# NUC1262AE register map
File version: 1.0
Registers are 32-bit, read-write, reset 0x0 unless marked. A register's access mark holds for its fields unless they carry their own. Offsets are from the block's base; [hi:lo] are bit positions; {n}, {i} and the like mark numbered series.

## SYS — SYS Register Map
Base 0x50000000
0x00 SYS_PDID ro reset not defined — Part Device Identification Number Register
  [31:0] PDID — Part Device Identification Number (Read Only). This register reflects device part number code. Software can read this register to identify which device is used.
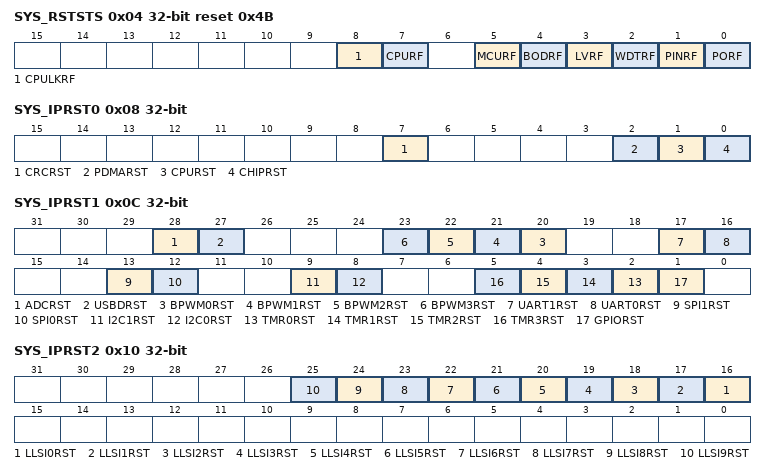
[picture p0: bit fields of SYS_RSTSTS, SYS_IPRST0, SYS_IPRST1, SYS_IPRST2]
0x04 SYS_RSTSTS reset 0x4B — System Reset Status Register
  [8] CPULKRF — CPU Lockup Reset Flag. The CPU lockup reset flag is set by hardware If Cortex-M23 lockup happened. Note 1: This bit can be cleared by software writing 1. Note 2: When CPU lockup happened under ICE is connected, this flag will be set to 1 but chip will not reset.
    0=No reset from CPU lockup happened; 1=The Cortex-M23 lockup happened and chip is reset
  [7] CPURF — CPU Reset Flag. The CPU reset flag is set by hardware if software writes CPURST (SYS_IPRST0[1]) 1 to reset Cortex-M23 Core and Flash Memory Controller (FMC). Note: This bit can be cleared by software writing 1.
    0=No reset from CPU; 1=The Cortex-M23 Core and FMC are reset by software setting CPURST to 1
  [5] MCURF — MCU Reset Flag. The MCU reset flag is set by the 'Reset Signal' from the Cortex-M23 Core to indicate the previous reset source. Note: This bit can be cleared by software writing 1.
    0=No reset from Cortex-M23; 1=The Cortex-M23 had issued the reset signal to reset the system by writing 1 to the bit SYSRESETREQ(AIRCR[2], Application Interrupt and Reset Control Register, address = 0xE000ED0C) in system control registers of Cortex-M23 core
  [4] BODRF — BOD Reset Flag. The BOD reset flag is set by the 'Reset Signal' from the Brown-out Detector to indicate the previous reset source. Note: This bit can be cleared by software writing 1.
    0=No reset from BOD; 1=The BOD had issued the reset signal to reset the system
  [3] LVRF — LVR Reset Flag. The LVR reset flag is set by the 'Reset Signal' from the Low Voltage Reset Controller to indicate the previous reset source. Note: This bit can be cleared by software writing 1.
    0=No reset from LVR; 1=LVR controller had issued the reset signal to reset the system
  [2] WDTRF — WDT Reset Flag. The WDT reset flag is set by the 'Reset Signal' from the Watchdog Timer or Window Watchdog Timer to indicate the previous reset source. Note 1: This bit can be cleared by software writing 1. Note 2: Watchdog Timer register RSTF(WDT_CTL[2]) bit is set if the system has been reset by WDT time-out reset. Window Watchdog Timer register WWDTRF(WWDT_STATUS[1]) bit is set if the system has been reset by WWDT time-out reset.
    0=No reset from watchdog timer or window watchdog timer; 1=The watchdog timer or window watchdog timer had issued the reset signal to reset the system
  [1] PINRF — nRESET Pin Reset Flag. The nRESET pin reset flag is set by the 'Reset Signal' from the nRESET Pin to indicate the previous reset source. Note: This bit can be cleared by software writing 1.
    0=No reset from nRESET pin; 1=Pin nRESET had issued the reset signal to reset the system
  [0] PORF — POR Reset Flag. The POR reset flag is set by the 'Reset Signal' from the Power-on Reset (POR) Controller or bit CHIPRST (SYS_IPRST0[0]) to indicate the previous reset source. Note: This bit can be cleared by software writing 1.
    0=No reset from POR or CHIPRST; 1=Power-on Reset (POR) or CHIPRST had issued the reset signal to reset the system
0x08 SYS_IPRST0 — Peripheral Reset Control Register 0
  [7] CRCRST — CRC Calculation Controller Reset (Write Protect). Set this bit to 1 will generate a reset signal to the CRC calculation controller. User needs to set this bit to 0 to release from the reset state. Note: This bit is write protected. Refer to the SYS_REGLCTL register.
    0=CRC calculation controller normal operation; 1=CRC calculation controller reset
  [2] PDMARST — PDMA Controller Reset (Write Protect). Setting this bit to 1 will generate a reset signal to the PDMA. User needs to set this bit to 0 to release from reset state. Note: This bit is write protected. Refer to the SYS_REGLCTL register.
    0=PDMA controller normal operation; 1=PDMA controller reset
  [1] CPURST — Processor Core One-shot Reset (Write Protect). Setting this bit will only reset the processor core and Flash Memory Controller (FMC), and this bit will automatically return to 0 after the 2 clock cycles. Note: This bit is write protected. Refer to the SYS_REGLCTL register.
    0=Processor core normal operation; 1=Processor core one-shot reset
  [0] CHIPRST — Chip One-shot Reset (Write Protect). Setting this bit will reset the whole chip, including Processor core and all peripherals, and this bit will automatically return to 0 after the 2 clock cycles. The CHIPRST is same as the POR reset, all the chip controllers is reset and the chip setting from Flash are also reload. About the difference between CHIPRST and SYSRESETREQ(AIRCR[2]), please refer to section 6.2.2. Note: This bit is write protected. Refer to the SYS_REGLCTL register.
    0=Chip normal operation; 1=Chip one-shot reset
0x0C SYS_IPRST1 — Peripheral Reset Control Register 1
  [28] ADCRST — ADC Controller Reset
    0=ADC controller normal operation; 1=ADC controller reset
  [27] USBDRST — USB Device Controller Reset
    0=USB device controller normal operation; 1=USB device controller reset
  [n+20] BPWM{n}RST (n=0..3) — BPWM{n} Controller Reset
    0=BPWM{n} controller normal operation; 1=BPWM{n} controller reset
  [17] UART1RST — UART1 Controller Reset
    0=UART1 controller normal operation; 1=UART1 controller reset
  [16] UART0RST — UART0 Controller Reset
    0=UART0 controller normal operation; 1=UART0 controller reset
  [13] SPI1RST — SPI1 Controller Reset
    0=SPI1 controller normal operation; 1=SPI1 controller reset
  [12] SPI0RST — SPI0 Controller Reset
    0=SPI0 controller normal operation; 1=SPI0 controller reset
  [9] I2C1RST — I2C1 Controller Reset
    0=I2C1 controller normal operation; 1=I2C1 controller reset
  [8] I2C0RST — I2C0 Controller Reset
    0=I2C0 controller normal operation; 1=I2C0 controller reset
  [n+2] TMR{n}RST (n=0..3) — Timer{n} Controller Reset
    0=Timer{n} controller normal operation; 1=Timer{n} controller reset
  [1] GPIORST — GPIO Controller Reset
    0=GPIO controller normal operation; 1=GPIO controller reset
0x10 SYS_IPRST2 — Peripheral Reset Control Register 2
  [n+16] LLSI{n}RST (n=0..9) — LLSI{n} Controller Reset
    0=LED Lighting Strip Interface {n} controller normal operation; 1=LED Lighting Strip Interface {n} controller reset
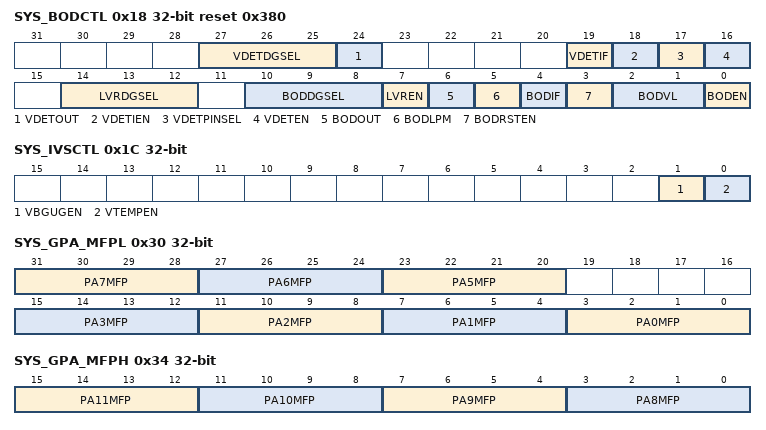
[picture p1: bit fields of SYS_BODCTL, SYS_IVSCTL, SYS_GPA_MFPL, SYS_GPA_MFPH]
0x18 SYS_BODCTL reset 0x380 (reset mask 0xFFFFFFF0) — Brown-out Detector Control Register
  [27:25] VDETDGSEL — Voltage Detector Output De-glitch Time Select (Write Protect). Note: These bits are write protected. Refer to the SYS_REGLCTL register.
    0=VDET output is sampled by VDET clock; 1=16 system clock (HCLK); 2=32 system clock (HCLK); 3=64 system clock (HCLK); 4=128 system clock (HCLK); 5=256 system clock (HCLK); 6=512 system clock (HCLK); 7=1024 system clock (HCLK)
  [24] VDETOUT — Voltage Detector Output Status. It means the detected voltage is lower than Band-gap. If the VDETEN is 0, VDET function is disabled. This bit always responds 0.
    0=VDET output status is 0; 1=VDET output status is 1
  [19] VDETIF — Voltage Detector Interrupt Flag. Note: This bit can be cleared by software writing 1.
    0=VDET does not detect any voltage draft at external pin down through or up through the voltage of Band-gap; 1=When VDET detects the external pin is dropped down through the voltage of Band-gap or the external pin is raised up through the voltage of Band-gap, this bit is set to 1 and the voltage detector interrupt is requested if voltage detector interrupt is enabled
  [18] VDETIEN — Voltage Detector Interrupt Enable Bit
    0=VDET interrupt Disabled; 1=VDET interrupt Enabled
  [17] VDETPINSEL — Voltage Detector External Input Voltage Pin Selection. Note 1: If VDET_P0 is selected, multi-function pin must be selected correctly in PB0MFP (SYS_GPB_MFPL[3:0]). Note 2: If VDET_P1 is selected, multi-function pin must be selected correctly in PB1MFP (SYS_GPB_MFPL[7:4]).
    0=The input voltage is from VDET_P0 (PB.0); 1=The input voltage is from VDET_P1 (PB.1)
  [16] VDETEN — Voltage Detector Enable Bit. Note 1: This function is still active in whole chip Power-down mode. Note 2: This function need use LIRC or LXT as VDET clock source, which is selected in VDETCKSEL (CLK_BODCLK[0]). Note2: The input pin for VDET detect voltage is selectable by VDETPINSEL (SYS_BODCTL[17]).
    0=VDET detect external input voltage function Disabled; 1=VDET detect external input voltage function Enabled
  [14:12] LVRDGSEL — LVR Output De-glitch Time Select (Write Protect). Note: These bits are write protected. Refer to the SYS_REGLCTL register.
    0=Without de-glitch function; 1=4 system clock (HCLK); 2=8 system clock (HCLK); 3=16 system clock (HCLK); 4=32 system clock (HCLK); 5=64 system clock (HCLK); 6=128 system clock (HCLK); 7=256 system clock (HCLK)
  [10:8] BODDGSEL — Brown-out Detector Output De-glitch Time Select (Write Protect). Note: These bits are write protected. Refer to the SYS_REGLCTL register.
    0=BOD output is sampled by RC10K clock; 1=4 system clock (HCLK); 2=8 system clock (HCLK); 3=16 system clock (HCLK); 4=32 system clock (HCLK); 5=64 system clock (HCLK); 6=128 system clock (HCLK); 7=256 system clock (HCLK)
  [7] LVREN — Low Voltage Reset Enable Bit (Write Protect). The LVR function resets the chip when the input power voltage is lower than LVR circuit setting. LVR function is enabled by default. Note 1: After enabling the bit, the LVR function will be active with 200us delay for LVR output stable (default). Note 2: This bit is write protected. Refer to the SYS_REGLCTL register.
    0=Low Voltage Reset function Disabled; 1=Low Voltage Reset function Enabled
  [6] BODOUT — Brown-out Detector Output Status. It means the detected voltage is lower than BODVL setting. If the BODEN is 0, BOD function is disabled. This bit always responds 0.
    0=Brown-out Detector output status is 0; 1=Brown-out Detector output status is 1
  [5] BODLPM — Brown-out Detector Low Power Mode (Write Protect). Note 1: The BOD consumes about 100uA in normal mode, the low power mode can reduce the current to about 1/10 but slow the BOD response. Note 2: This bit is write protected. Refer to the SYS_REGLCTL register.
    0=BOD operated in normal mode (default); 1=BOD Low Power mode Enabled
  [4] BODIF — Brown-out Detector Interrupt Flag. Note: This bit can be cleared by software writing 1.
    0=Brown-out Detector does not detect any voltage draft at VDD down through or up through the voltage of BODVL setting; 1=When Brown-out Detector detects the VDD is dropped down through the voltage of BODVL setting or the VDD is raised up through the voltage of BODVL setting, this bit is set to 1 and the brown-out interrupt is requested if brown-out interrupt is enabled
  [3] BODRSTEN — Brown-out Reset Enable Bit (Write Protect). The default value is set by Flash controller user configuration register CBORST(CONFIG0[20]) bit. Note 1: While the Brown-out Detector function is enabled (BODEN high) and BOD reset function is enabled (BODRSTEN high), BOD will assert a signal to reset chip when the detected voltage is lower than the threshold (BODOUT high). While the BOD function is enabled (BODEN high) and BOD interrupt function is enabled (BODRSTEN low), BOD will assert an interrupt if BODOUT is high. BOD interrupt will keep till to the BODEN set to 0. BOD interrupt can be blocked by disabling the NVIC BOD interrupt or disabling BOD function (set BODEN low). Note 2: This bit is write protected. Refer to the SYS_REGLCTL register.
    0=Brown-out 'INTERRUPT' function Enabled; 1=Brown-out 'RESET' function Enabled
  [2:1] BODVL — Brown-out Detector Threshold Voltage Selection (Write Protect). The default value is set by Flash controller user configuration register CBOV (CONFIG0 [22:21]). Note: These bits are write protected. Refer to the SYS_REGLCTL register.
    0=Brown-Out Detector threshold voltage is 2.2V; 1=Brown-Out Detector threshold voltage is 2.7V; 2=Brown-Out Detector threshold voltage is 3.7V; 3=Brown-Out Detector threshold voltage is 4.5V
  [0] BODEN — Brown-out Detector Enable Bit (Write Protect). The default value is set by Flash controller user configuration register CBODEN (CONFIG0 [23]). Note: This bit is write protected. Refer to the SYS_REGLCTL register.
    0=Brown-out Detector function Disabled; 1=Brown-out Detector function Enabled
0x1C SYS_IVSCTL — Internal Voltage Source Control Register
  [1] VBGUGEN — Band-gap VBG Unity Gain Buffer Enable Bit. This bit is used to enable/disable Band-gap VBG unity gain buffer function. Note: After this bit is set to 1, the value of VBG unity gain buffer output voltage can be obtained from ADC conversion result. Please refer to ADC function chapter for details.
    0=VBG unity gain buffer function Disabled (default); 1=VBG unity gain buffer function Enabled
  [0] VTEMPEN — Temperature Sensor Enable Bit. This bit is used to enable/disable temperature sensor function. Note: After this bit is set to 1, the value of temperature sensor output can be obtained from ADC conversion result. Please refer to ADC function chapter for details.
    0=Temperature sensor function Disabled (default); 1=Temperature sensor function Enabled
0x24 SYS_PORCTL — Power-on Reset Controller Register
  [15:0] POROFF — Power-on Reset Enable Bit (Write Protect). When powered on, the POR circuit generates a reset signal to reset the whole chip function, but noise on the power may cause the POR active again. User can disable internal POR circuit to avoid unpredictable noise to cause chip reset by writing 0x5AA5 to this field. The POR function will be active again when this field is set to another value or chip is reset by other reset source, including: nRESET, Watchdog, LVR reset, BOD reset, ICE reset command and the software-chip reset function. Note: These bits are write protected. Refer to the SYS_REGLCTL register.
0x30 SYS_GPA_MFPL — GPIOA Low Byte Multiple Function Control Register
  [31:28] PA7MFP — PA.7 Multi-function Pin Selection
  [27:24] PA6MFP — PA.6 Multi-function Pin Selection
  [23:20] PA5MFP — PA.5 Multi-function Pin Selection
  [15:12] PA3MFP — PA.3 Multi-function Pin Selection
  [11:8] PA2MFP — PA.2 Multi-function Pin Selection
  [7:4] PA1MFP — PA.1 Multi-function Pin Selection
  [3:0] PA0MFP — PA.0 Multi-function Pin Selection
0x34 SYS_GPA_MFPH — GPIOA High Byte Multiple Function Control Register
  [15:12] PA11MFP — PA.11 Multi-function Pin Selection
  [11:8] PA10MFP — PA.10 Multi-function Pin Selection
  [7:4] PA9MFP — PA.9 Multi-function Pin Selection
  [3:0] PA8MFP — PA.8 Multi-function Pin Selection
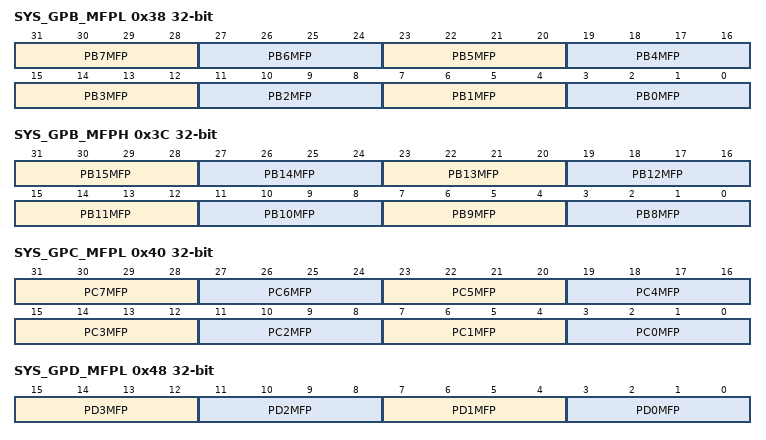
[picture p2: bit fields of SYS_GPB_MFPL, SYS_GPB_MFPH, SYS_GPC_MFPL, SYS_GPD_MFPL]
0x38 SYS_GPB_MFPL — GPIOB Low Byte Multiple Function Control Register
  [31:28] PB7MFP — PB.7 Multi-function Pin Selection
  [27:24] PB6MFP — PB.6 Multi-function Pin Selection
  [23:20] PB5MFP — PB.5 Multi-function Pin Selection
  [19:16] PB4MFP — PB.4 Multi-function Pin Selection
  [15:12] PB3MFP — PB.3 Multi-function Pin Selection
  [11:8] PB2MFP — PB.2 Multi-function Pin Selection
  [7:4] PB1MFP — PB.1 Multi-function Pin Selection
  [3:0] PB0MFP — PB.0 Multi-function Pin Selection
0x3C SYS_GPB_MFPH — GPIOB High Byte Multiple Function Control Register
  [31:28] PB15MFP — PB.15 Multi-function Pin Selection
  [27:24] PB14MFP — PB.14 Multi-function Pin Selection
  [23:20] PB13MFP — PB.13 Multi-function Pin Selection
  [19:16] PB12MFP — PB.12 Multi-function Pin Selection
  [15:12] PB11MFP — PB.11 Multi-function Pin Selection
  [11:8] PB10MFP — PB.10 Multi-function Pin Selection
  [7:4] PB9MFP — PB.9 Multi-function Pin Selection
  [3:0] PB8MFP — PB.8 Multi-function Pin Selection
0x40 SYS_GPC_MFPL — GPIOC Low Byte Multiple Function Control Register
  [31:28] PC7MFP — PC.7 Multi-function Pin Selection
  [27:24] PC6MFP — PC.6 Multi-function Pin Selection
  [23:20] PC5MFP — PC.5 Multi-function Pin Selection
  [19:16] PC4MFP — PC.4 Multi-function Pin Selection
  [15:12] PC3MFP — PC.3 Multi-function Pin Selection
  [11:8] PC2MFP — PC.2 Multi-function Pin Selection
  [7:4] PC1MFP — PC.1 Multi-function Pin Selection
  [3:0] PC0MFP — PC.0 Multi-function Pin Selection
0x44 SYS_GPC_MFPH — GPIOC High Byte Multiple Function Control Register
  [27:24] PC14MFP — PC14 Multi-function Pin Selection
0x48 SYS_GPD_MFPL — GPIOD Low Byte Multiple Function Control Register
  [15:12] PD3MFP — PD.3 Multi-function Pin Selection
  [11:8] PD2MFP — PD.2 Multi-function Pin Selection
  [7:4] PD1MFP — PD.1 Multi-function Pin Selection
  [3:0] PD0MFP — PD.0 Multi-function Pin Selection
0x4C SYS_GPD_MFPH — GPIOD High Byte Multiple Function Control Register
  [31:28] PD15MFP — PD.15 Multi-function Pin Selection
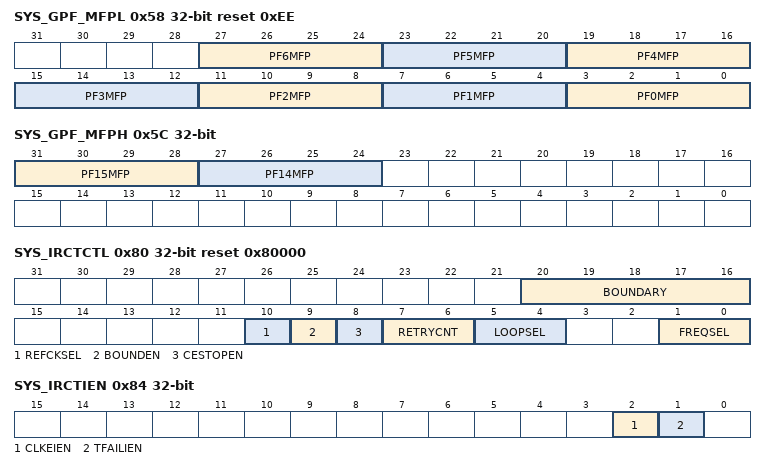
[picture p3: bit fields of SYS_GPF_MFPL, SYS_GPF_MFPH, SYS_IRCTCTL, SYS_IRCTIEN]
0x58 SYS_GPF_MFPL reset 0xEE — GPIOF Low Byte Multiple Function Control Register
  [27:24] PF6MFP — PF.6 Multi-function Pin Selection
  [23:20] PF5MFP — PF.5 Multi-function Pin Selection
  [19:16] PF4MFP — PF.4 Multi-function Pin Selection
  [15:12] PF3MFP — PF.3 Multi-function Pin Selection
  [11:8] PF2MFP — PF.2 Multi-function Pin Selection
  [7:4] PF1MFP — PF.1 Multi-function Pin Selection
  [3:0] PF0MFP — PF.0 Multi-function Pin Selection
0x5C SYS_GPF_MFPH — GPIOF High Byte Multiple Function Control Register
  [31:28] PF15MFP — PF.15 Multi-function Pin Selection
  [27:24] PF14MFP — PF.14 Multi-function Pin Selection
0x80 SYS_IRCTCTL reset 0x80000 — HIRC Trim Control Register
  [20:16] BOUNDARY — Boundary Selection. Fill the boundary range from 0x1 to 0x1F, 0x0 is reserved. Note: This field is effective only when the BOUNDEN(SYS_IRCTCTL[9]) is enabled.
  [10] REFCKSEL — Reference Clock Selection
    0=HIRC trim reference clock is from LXT (32.768 kHz); 1=HIRC trim reference clock is from USB synchronous mode packet
  [9] BOUNDEN — Boundary Enable Bit
    0=Boundary function Disabled; 1=Boundary function Enabled
  [8] CESTOPEN — Clock Error Stop Enable Bit
    0=The trim operation is keep going if clock is inaccurate; 1=The trim operation is stopped if clock is inaccurate
  [7:6] RETRYCNT — Trim Value Update Limitation Count. This field defines that how many times the auto trim circuit will try to update the HIRC trim value before the frequency of HIRC locked. Once the HIRC locked, the internal trim value update counter will be reset. If the trim value update counter reached this limitation value and frequency of HIRC is still not locked, the auto trim operation will be disabled and FREQSEL(SYS_IRCTCTL[1:0]) will be cleared to 00.
    0=Trim retry count limitation is 64 loops; 1=Trim retry count limitation is 128 loops; 2=Trim retry count limitation is 256 loops; 3=Trim retry count limitation is 512 loops
  [5:4] LOOPSEL — Trim Calculation Loop Selection. This field defines that trim value calculation is based on how many clocks of reference clock (32.768 kHz, LXT). Note: For example, if LOOPSEL is set as 00, auto trim circuit will calculate trim value based on the average frequency difference in 4 clocks of reference clock.
    0=Trim value calculation is based on average difference in 4 clocks of reference clock; 1=Trim value calculation is based on average difference in 8 clocks of reference clock; 2=Trim value calculation is based on average difference in 16 clocks of reference clock; 3=Trim value calculation is based on average difference in 32 clocks of reference clock
  [1:0] FREQSEL — Trim Frequency Selection. This field indicates the target frequency of internal high speed RC oscillator (HIRC) auto trim. During auto trim operation, if clock error detected with CESTOPEN(SYS_IRCTCTL[8]) is set to 1 or trim retry limitation count reached, this field will be cleared to 00 automatically.
    0=Disable HIRC auto trim function; 1=Enable HIRC auto trim function and trim HIRC to 48 MHz
0x84 SYS_IRCTIEN — HIRC Trim Interrupt Enable Register
  [2] CLKEIEN — HIRC Clock Error Interrupt Enable Bit. This bit controls if CPU would get an interrupt while HIRC clock is inaccurate during auto trim operation. If this bit is set to1, and CLKERRIF(SYS_IRCTSTS[2]) is set during auto trim operation, an interrupt will be triggered to notify the clock frequency is inaccurate.
    0=Disable CLKERRIF(SYS_IRCTSTS[2]) status to trigger an interrupt to CPU; 1=Enable CLKERRIF(SYS_IRCTSTS[2]) status to trigger an interrupt to CPU
  [1] TFAILIEN — HIRC Trim Failure Interrupt Enable Bit. This bit controls if an interrupt will be triggered while HIRC trim value update limitation count reached and HIRC frequency still not locked on target frequency set by FREQSEL(SYS_IRCTCTL[1:0]). If this bit is high and TFAILIF(SYS_IRCTSTS[1]) is set during auto trim operation, an interrupt will be triggered to notify that HIRC trim value update limitation count reached.
    0=Disable TFAILIF(SYS_IRCTSTS[1]) status to trigger an interrupt to CPU; 1=Enable TFAILIF(SYS_IRCTSTS[1]) status to trigger an interrupt to CPU
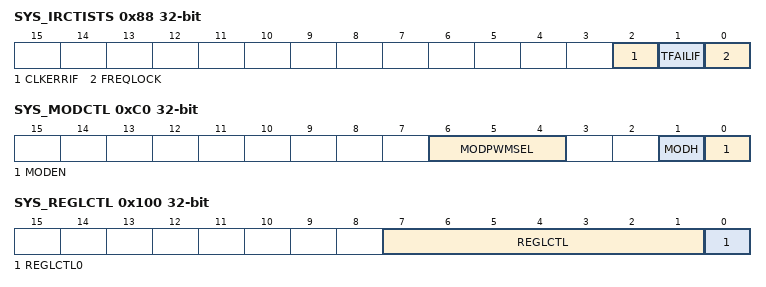
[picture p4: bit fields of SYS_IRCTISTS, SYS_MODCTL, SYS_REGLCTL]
0x88 SYS_IRCTISTS — HIRC Trim Interrupt Status Register
  [2] CLKERRIF — Clock Error Interrupt Status. When the frequency of 32.768 kHz external low speed crystal oscillator (LXT) or 48 MHz internal high speed RC oscillator (HIRC) is shift larger to unreasonable value, this bit will be set and indicate that clock frequency is inaccurate. Once this bit is set to 1, the auto trim operation stopped and FREQSEL(SYS_IRCTCL[1:0]) will be cleared to 00 by hardware automatically if CESTOPEN(SYS_IRCTCTL[8]) is set to 1. If this bit is set and CLKEIEN(SYS_IRCTIEN[2]) is high, an interrupt will be triggered to notify the clock frequency is inaccurate. Write 1 to clear this to 0.
    0=Clock frequency is accurate; 1=Clock frequency is inaccurate
  [1] TFAILIF — Trim Failure Interrupt Status. This bit indicates that HIRC trim value update limitation count reached and the HIRC clock frequency is still not locked. Once this bit is set, the auto trim operation stopped and FREQSEL(SYS_IRCTCTL[1:0]) will be cleared to 00 by hardware automatically. If this bit is set and TFAILIEN(SYS_IRCTIEN[1]) is high, an interrupt will be triggered to notify that HIRC trim value update limitation count reached. Write 1 to clear this to 0.
    0=Trim value update limitation count not reached; 1=Trim value update limitation count reached and HIRC frequency still not locked
  [0] FREQLOCK — HIRC Frequency Lock Status. This bit indicates the HIRC frequency is locked. This is a status bit and does not trigger any interrupt.
    0=The internal high-speed RC oscillator frequency is not locked at 48 MHz yet; 1=The internal high-speed RC oscillator frequency locked at 48 MHz
0xC0 SYS_MODCTL — Modulation Control Register
  [6:4] MODPWMSEL — BPWM0 Channel Select for Modulation. Select the BPWM0 channel to modulate with the UART1_TXD. Note: These bits are valid while MODEN (SYS_MODCTL[0]) is set to 1.
    {v}=BPWM0 channel {v} modulate with UART1_TXD (v=0..3)
  [1] MODH — Modulation at Data High. Select modulation pulse (BPWM) at UART1_TXD high or low.
    0=Modulation pulse at UART1_TXD low; 1=Modulation pulse at UART1_TXD high
  [0] MODEN — Modulation Function Enable Bit. This bit enables modulation function by modulating with BPWM channel output and UART1_TXD.
    0=Modulation Function Disabled; 1=Modulation Function Enabled
0x100 SYS_REGLCTL — Register Lock Control Register
  [7:1] REGLCTL — Register Lock Control Code. Some registers have write-protection function. Writing these registers have to disable the protected function by writing the sequence value '59h', '16h', '88h' to this field. After this sequence is completed, the REGLCTL bit will be set to 1 and write-protection registers can be normal write.
  [0] REGLCTL0 — Register Lock Control Disable Index. The Protected registers are: SYS_IPRST0: address 0x5000_0008. SYS_BODCTL: address 0x5000_0018. SYS_PORCTL: address 0x5000_0024. SYS_SRAM_BISTCTL: address 0x5000_00D0. CLK_PWRCTL: address 0x5000_0200. CLK_APBCLK0: address 0x5000_0208. CLK_CLKSEL0: address 0x5000_0210. CLK_CLKSEL1: address 0x5000_0214. CLK_CLKSEL3: address 0x5000_0234. CLK_CLKDSTS: address 0x5000_0274. FMC_ISPCTL: address 0x5000_C000 (Flash ISP Control register). FMC_ISPTRG: address 0x5000_C010 (ISP Trigger Control register). FMC_FTCTL: address 0x5000_C018. FMC_ISPSTS: address 0x5000_C040. WDT_CTL: address 0x4000_4000. BPWM0_CTL0: address 0x4004_0000. BPWM1_CTL0: address 0x4014_0000. BPWM2_CTL0: address 0x4004_4000. BPWM3_CTL0: address 0x4014_4000. TIMER0_CTL: address 0x4001_0000. TIMER1_CTL: address 0x4001_0020. TIMER2_CTL: address 0x4011_0000. TIMER3_CTL: address 0x4011_0020
    0=Write-protection Enabled for writing protected registers. Any write to the protected register is ignored; 1=Write-protection Disabled for writing protected registers
0x114 SYS_TSOFFSET ro (reset mask 0xFFFFF000) — Temperature Sensor Offset Register
  [11:0] VTEMP — Temperature Sensor Offset Value (Read Only). This field reflects temperature sensor output voltage offset at 25oC from Flash.
